AUTOSAR XML (schema 4-3-0)
package /Impl_SWC_SCP_ARPkg
  swc implementation Impl_SWC_SCP_type: programming-language=C, sw-version=1.0.0, vendor-id=0, behavior=SWC_SCP_type_IB
    code-descriptors:
      code SRC: artifact-descriptors=autosar-engineering-object={short-label=EngObject, category=SWSRC}
    resource consumption ResourceConsumption
      memory section Mem_SWC_SCP_CAL: size=0, sw-addrmethod=CAL, symbol=CAL
      memory section Mem_SWC_SCP_CODE: size=0, sw-addrmethod=CODE, symbol=CODE
package /Impl_Type_SCP_ARPkg
  impl type BSCP_outputs: category=STRUCTURE
    6 x element, all with category=TYPE_REFERENCE, implementation-data-type=float32:
      VSCP_CAN3GWESC1toNIDECVehSpeedtoNidec_kph
      VSCP_CAN3GWIVI6toNIDECIVITimeSecondtoNidec_s
      VSCP_CAN3GWIVI6toNIDECIVITimeMonthtoNidec_MONTH
      VSCP_CAN3GWIVI6toNIDECIVITimeHourtoNidec_hr
      VSCP_CAN3GWIVI6toNIDECIVITimeDaytoNidec_DAY
      VSCP_CAN3GWIVI6toNIDECIVITimeMinutetoNidec_min
package /Interface_SCP_ARPkg
  sender receiver interface IF_BSCP_outputs
    data BSCP_outputs: type=BSCP_outputs
package /SWC_SCP_ARPkg
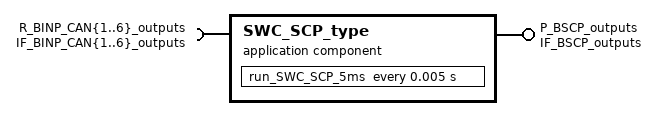
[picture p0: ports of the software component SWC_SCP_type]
  application sw component type SWC_SCP_type
    provide port P_BSCP_outputs: provided-interface=IF_BSCP_outputs
    6 x require port:
      R_BINP_CAN{1..6}_outputs: required-interface=IF_BINP_CAN{1..6}_outputs
    behavior SWC_SCP_type_IB: handle-termination-and-restart=NO-SUPPORT
      timing event TE_SCP_5ms: start-on-event=run_SWC_SCP_5ms, period=0.005
      runnable run_SWC_SCP_5ms
        data-receive-point-by-arguments:
          6 x access:
            drparg_BINP_CAN{1..6}_outputs: accessed-variable=R_BINP_CAN{1..6}_outputs.BINP_CAN{1..6}_outputs
        data-send-points:
          access dsp_BSCP_outputs: accessed-variable=P_BSCP_outputs.BSCP_outputs
